AUTOSAR XML (schema 00044)
standard types defined: uint8
package /MyDataTypes
  impl type My_uint8: category=VALUE, base-type=uint8, range phys 0..255, raw 0..255
package /INTERFACES
  sender receiver interface SR_DoorLock
    data DoorState: type=My_uint8
  client server interface CS_LedSwitch
    operation LedSwitch: possible-error=[E_OK, E_NOT_OK]
      arg LedState: type=My_uint8, direction=IN
    error E_OK: error-code=0
    error E_NOT_OK: error-code=1
package /SWCs
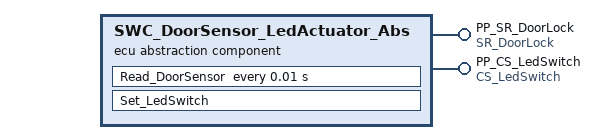
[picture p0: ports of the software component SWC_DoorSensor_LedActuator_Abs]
  ecu abstraction sw component type SWC_DoorSensor_LedActuator_Abs
    provide port PP_SR_DoorLock: provided-interface=SR_DoorLock
    provide port PP_CS_LedSwitch: provided-interface=CS_LedSwitch
    behavior IB_SWC_DoorSensor_LedActuator_Abs
      timing event TE_10ms: start-on-event=Read_DoorSensor, period=0.01
      operation invoked event OIE_LedSwitch: start-on-event=Set_LedSwitch, operation=PP_CS_LedSwitch.LedSwitch
      runnable Read_DoorSensor: symbol=Read_DoorSensor_Runnable
        data-write-access:
          access DoorState_DataWrite: accessed-variable=PP_SR_DoorLock.DoorState
      runnable Set_LedSwitch: symbol=Set_LedSwitch_Runnable
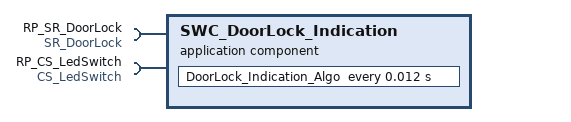
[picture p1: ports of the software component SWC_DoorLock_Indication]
  application sw component type SWC_DoorLock_Indication
    require port RP_SR_DoorLock: required-interface=SR_DoorLock
    require port RP_CS_LedSwitch: required-interface=CS_LedSwitch
    behavior IB_SWC_DoorLock_Indication
      timing event TE_12ms: start-on-event=DoorLock_Indication_Algo, period=0.012
      runnable DoorLock_Indication_Algo: symbol=DoorLock_Indication_Algo_Runnable
        data-read-access:
          access DoorState_DataRead: accessed-variable=RP_SR_DoorLock.DoorState
        sync call Sync_ServerCall: operation=RP_CS_LedSwitch.LedSwitch
package /COMPOSITIONs
  composition sw component type SWC_Composite_DoorLock_Indication
    component SWC1_EcuAbs_Type: type=SWC_DoorSensor_LedActuator_Abs
    component SWC2_APP_Type: type=SWC_DoorLock_Indication
    connect SWC1_EcuAbs_Type.PP_SR_DoorLock -> SWC2_APP_Type.RP_SR_DoorLock
    connect SWC1_EcuAbs_Type.PP_CS_LedSwitch -> SWC2_APP_Type.RP_CS_LedSwitch
